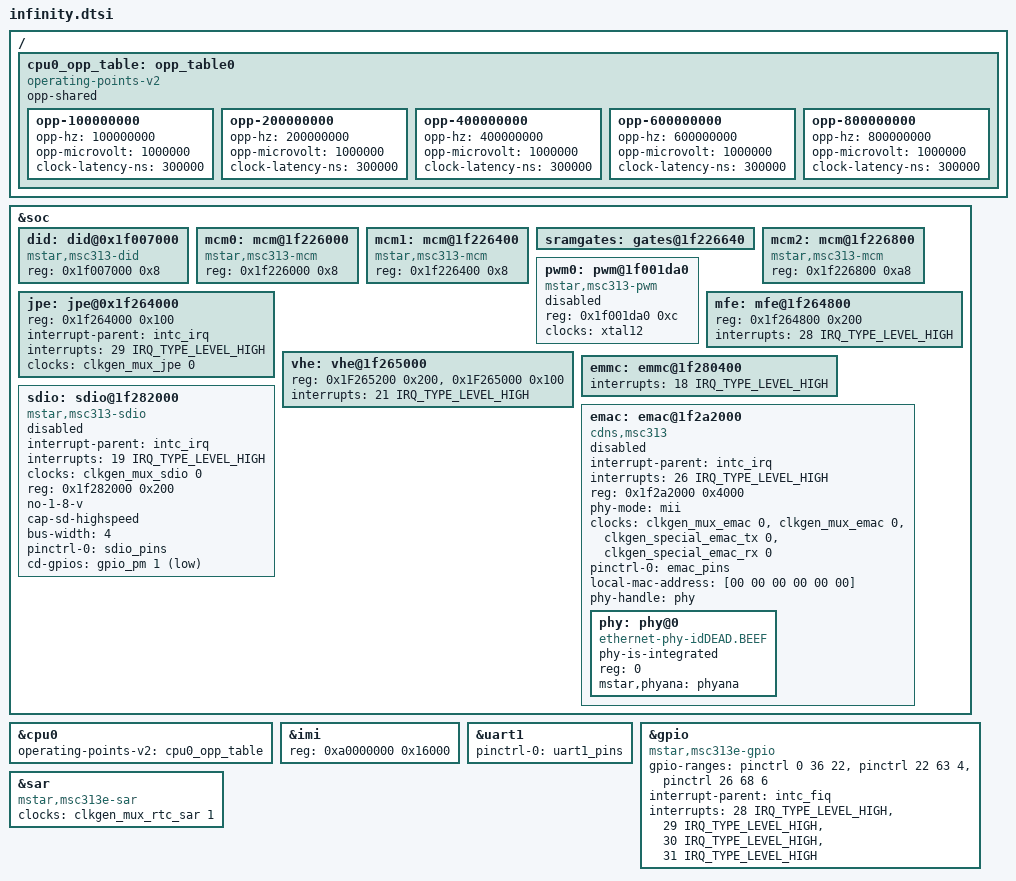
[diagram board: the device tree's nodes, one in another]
// SPDX-License-Identifier: GPL-2.0-or-later
/*
 * Copyright (c) 2020 thingy.jp.
 * Author: Daniel Palmer <daniel@thingy.jp>
 */

#include "mstar-v7.dtsi"

#include <dt-bindings/gpio/gpio.h>

/ {
	cpu0_opp_table: opp_table0 {
		compatible = "operating-points-v2";
		opp-shared;

		opp-100000000 {
			opp-hz = /bits/ 64 <100000000>;
			opp-microvolt = <1000000>;
			clock-latency-ns = <300000>;
		};

		opp-200000000 {
			opp-hz = /bits/ 64 <200000000>;
			opp-microvolt = <1000000>;
			clock-latency-ns = <300000>;
		};

		opp-400000000 {
			opp-hz = /bits/ 64 <400000000>;
			opp-microvolt = <1000000>;
			clock-latency-ns = <300000>;
		};
		opp-600000000 {
			opp-hz = /bits/ 64 <600000000>;
			opp-microvolt = <1000000>;
			clock-latency-ns = <300000>;
		};

		opp-800000000 {
			opp-hz = /bits/ 64 <800000000>;
			opp-microvolt = <1000000>;
			clock-latency-ns = <300000>;
		};
	};
};

&soc {
        did: did@0x1f007000 {
			compatible = "mstar,msc313-did";
			reg = <0x1f007000 0x8>;
        };

	mcm0: mcm@1f226000 {
		compatible = "mstar,msc313-mcm";
		reg = <0x1f226000 0x8>;
	};

	mcm1: mcm@1f226400 {
		compatible = "mstar,msc313-mcm";
		reg = <0x1f226400 0x8>;
		/*1f226400 */
		/*1f226404 */
		/*1f226408 */
	};

	sramgates: gates@1f226640 {
	};

	mcm2: mcm@1f226800 {
		compatible = "mstar,msc313-mcm";
		reg = <0x1f226800 0xa8>;
	};

	pwm0: pwm@1f001da0 {
		compatible = "mstar,msc313-pwm";
		reg = <0x1f001da0 0xc>;
		#pwm-cells = <2>;
		clocks = <&xtal12>;
		status = "disabled";
	};

	/* jpe - jpeg encoder */
	jpe: jpe@0x1f264000 {
		reg = <0x1f264000 0x100>;
		interrupt-parent = <&intc_irq>;
		interrupts = <29 IRQ_TYPE_LEVEL_HIGH>;
		clocks = <&clkgen_mux_jpe 0>;
	};

	/* mfe - video encoder*/
	mfe: mfe@1f264800 {
		reg = <0x1f264800 0x200>;
		interrupts = <28 IRQ_TYPE_LEVEL_HIGH>;
	};

	/* vhe - hevc encoder? English in comments is very good
	 * so likely this is an IP block
	 */
	vhe: vhe@1f265000 {
		reg = <0x1F265200 0x200>,
		      <0x1F265000 0x100>;
		interrupts = <21 IRQ_TYPE_LEVEL_HIGH>;
	};

	emmc: emmc@1f280400 {
		interrupts = <18 IRQ_TYPE_LEVEL_HIGH>;
	};

	sdio: sdio@1f282000 {
		compatible = "mstar,msc313-sdio";
		interrupt-parent = <&intc_irq>;
		interrupts = <19 IRQ_TYPE_LEVEL_HIGH>;
		clocks = <&clkgen_mux_sdio 0>;
		reg = <0x1f282000 0x200>;
		no-1-8-v;
		cap-sd-highspeed;
		bus-width = <4>;
		pinctrl-names = "default";
		pinctrl-0 = <&sdio_pins>;
		cd-gpios = <&gpio_pm 1 GPIO_ACTIVE_LOW>;
		status = "disabled";
	};

	emac: emac@1f2a2000 {
		#address-cells = <1>;
		#size-cells = <0>;
		compatible = "cdns,msc313";
		interrupt-parent = <&intc_irq>;
		interrupts = <26 IRQ_TYPE_LEVEL_HIGH>;
		reg = <0x1f2a2000 0x4000>;
		phy-mode = "mii";
		clock-names = "pclk", "hclk", "tx_clk", "rx_clk";
		clocks = <&clkgen_mux_emac 0>, 
				 <&clkgen_mux_emac 0>, 
				 <&clkgen_special_emac_tx 0>, 
				 <&clkgen_special_emac_rx 0>;
		pinctrl-names = "default";
		pinctrl-0 = <&emac_pins>;
		local-mac-address = [00 00 00 00 00 00];
		status = "disabled";
		phy-handle = <&phy>;
		phy: phy@0 {
			compatible = "ethernet-phy-idDEAD.BEEF";
			phy-is-integrated;
			reg = <0>;
			mstar,phyana = <&phyana>;
		};
	};
};

&cpu0 {
	operating-points-v2 = <&cpu0_opp_table>;
};

&imi {
	reg = <0xa0000000 0x16000>;
};

&uart1 {
	pinctrl-names = "default";
	pinctrl-0 = <&uart1_pins>;
};

&gpio {
	compatible = "mstar,msc313e-gpio";
	gpio-ranges = <&pinctrl 0 36 22>,
		      <&pinctrl 22 63 4>,
		      <&pinctrl 26 68 6>;
	interrupt-parent = <&intc_fiq>;
	interrupt-names = "spi0_cz",
			  "spi0_ck",
			  "spi0_di",
			  "spi0_do";
	interrupts = <28 IRQ_TYPE_LEVEL_HIGH>,
		     <29 IRQ_TYPE_LEVEL_HIGH>,
		     <30 IRQ_TYPE_LEVEL_HIGH>,
		     <31 IRQ_TYPE_LEVEL_HIGH>;
	status = "okay";
};

&sar {
	compatible = "mstar,msc313e-sar";
	clocks = <&clkgen_mux_rtc_sar 1>;
	clock-names = "sar_clk";
};
